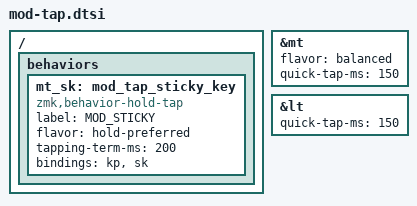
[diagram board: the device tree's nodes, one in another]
#define MT_SK(mod) &mt_sk mod mod

&mt {
    flavor = "balanced";
    quick-tap-ms = <150>;
};

&lt {
    quick-tap-ms = <150>;
};

/ {
  behaviors {
    mt_sk: mod_tap_sticky_key {
    	compatible = "zmk,behavior-hold-tap";
    	label = "MOD_STICKY";
    	#binding-cells = <2>;
    	flavor = "hold-preferred";
    	tapping-term-ms = <200>;
    	bindings = <&kp>, <&sk>;
    };
  };
};
